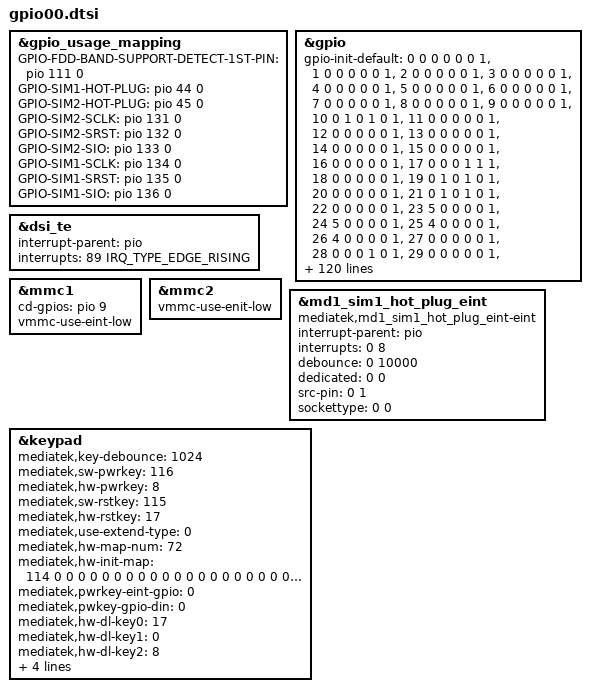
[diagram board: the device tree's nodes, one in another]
// SPDX-License-Identifier: (GPL-2.0 OR MIT)
/*
 * Copyright (C) 2025 MediaTek Inc.
 */
/*
 * Generated by MTK SP DrvGen Version: 3.5.160809 for MT6991.
 * 2025-01-08 15:47:34
 * Do Not Modify The File.
 * Copyright Mediatek Inc. (c) 2016.
 */

/*************************
 * ADC DTSI File
 ************************/



/*************************
 * CLK_BUF DTSI File
 ************************/



/*************************
 * I2C DTSI File
 ************************/



/*************************
 * GPIO DTSI File
 ************************/

&gpio_usage_mapping {
	GPIO-FDD-BAND-SUPPORT-DETECT-1ST-PIN = <&pio 111 0>;
	GPIO-SIM1-HOT-PLUG = <&pio 44 0>;
	GPIO-SIM2-HOT-PLUG = <&pio 45 0>;
	GPIO-SIM2-SCLK = <&pio 131 0>;
	GPIO-SIM2-SRST = <&pio 132 0>;
	GPIO-SIM2-SIO = <&pio 133 0>;
	GPIO-SIM1-SCLK = <&pio 134 0>;
	GPIO-SIM1-SRST = <&pio 135 0>;
	GPIO-SIM1-SIO = <&pio 136 0>;
};

#if 0
&mt6373_gpio{
	/* gpio1 and gpio2 has been reserved */
	mt6373-gpio-init-default = <3 0 0 0 1 0 0>,
	<4 0 0 0 1 0 0>,
	<5 0 0 0 1 0 0>,
	<6 0 0 0 1 0 0>,
	<7 0 0 0 1 0 0>,
	<8 0 0 0 1 0 0>,
	<9 0 0 0 1 0 0>,
	<10 0 0 0 1 0 0>,
	<11 0 0 0 1 1 0>,
	<12 0 0 0 1 1 0>,
	<13 0 0 0 0 0 0>;
};
#endif

&gpio{
	gpio-init-default = <0 0 0 0 0 0 1>,
		<1 0 0 0 0 0 1>,
		<2 0 0 0 0 0 1>,
		<3 0 0 0 0 0 1>,
		<4 0 0 0 0 0 1>,
		<5 0 0 0 0 0 1>,
		<6 0 0 0 0 0 1>,
		<7 0 0 0 0 0 1>,
		<8 0 0 0 0 0 1>,
		<9 0 0 0 0 0 1>,
		<10 0 1 0 1 0 1>,
		<11 0 0 0 0 0 1>,
		<12 0 0 0 0 0 1>,
		<13 0 0 0 0 0 1>,
		<14 0 0 0 0 0 1>,
		<15 0 0 0 0 0 1>,
		<16 0 0 0 0 0 1>,
		<17 0 0 0 1 1 1>,
		<18 0 0 0 0 0 1>,
		<19 0 1 0 1 0 1>,
		<20 0 0 0 0 0 1>,
		<21 0 1 0 1 0 1>,
		<22 0 0 0 0 0 1>,
		<23 5 0 0 0 0 1>,
		<24 5 0 0 0 0 1>,
		<25 4 0 0 0 0 1>,
		<26 4 0 0 0 0 1>,
		<27 0 0 0 0 0 1>,
		<28 0 0 0 1 0 1>,
		<29 0 0 0 0 0 1>,
		<30 0 0 0 0 0 1>,
		<31 0 0 0 0 0 1>,
		<32 0 0 0 0 0 1>,
		<33 0 0 0 0 0 1>,
		<34 0 1 0 1 0 1>,
		<35 0 0 0 0 0 1>,
		<36 0 1 0 1 0 1>,
		<37 0 0 0 1 0 1>,
		<38 0 0 0 1 0 1>,
		<39 0 1 0 1 0 1>,
		<40 4 0 0 1 0 1>,
		<41 4 0 0 1 0 1>,
		<42 4 0 0 1 0 1>,
		<43 4 0 0 1 0 1>,
		<44 1 0 0 0 0 1>,
		<45 0 0 0 1 0 1>,
		<46 1 0 0 1 1 1>,
		<47 1 0 0 1 1 1>,
		<48 1 0 0 1 1 1>,
		<49 1 0 0 1 1 1>,
		<50 1 0 0 1 1 1>,
		<51 1 0 0 1 1 1>,
		<52 0 0 0 1 0 1>,
		<53 0 0 0 1 0 1>,
		<54 0 0 0 1 0 1>,
		<55 0 0 0 1 0 1>,
		<56 1 0 0 0 0 1>,
		<57 1 0 0 0 0 1>,
		<58 0 0 0 1 0 1>,
		<59 0 0 0 1 0 1>,
		<60 1 0 0 1 1 1>,
		<61 1 0 0 0 0 1>,
		<62 1 0 0 0 0 1>,
		<63 1 0 0 0 0 1>,
		<64 1 0 0 1 1 1>,
		<65 0 0 0 1 0 1>,
		<66 1 0 0 0 0 1>,
		<67 1 0 0 0 0 1>,
		<68 1 0 0 0 0 1>,
		<69 1 0 0 1 0 1>,
		<70 0 0 0 1 0 1>,
		<71 0 0 0 0 0 1>,
		<72 0 0 0 1 0 1>,
		<73 0 0 0 1 0 1>,
		<74 0 0 0 1 0 1>,
		<75 1 0 0 0 0 1>,
		<76 1 0 0 0 0 1>,
		<77 1 0 0 1 0 1>,
		<78 1 0 0 1 0 1>,
		<79 0 1 0 1 0 1>,
		<80 0 1 0 1 0 1>,
		<81 2 0 0 1 0 1>,
		<82 2 0 0 1 1 1>,
		<83 2 0 0 1 0 1>,
		<84 2 0 0 1 0 1>,
		<85 1 0 0 1 0 1>,
		<86 1 0 0 1 1 1>,
		<87 1 0 0 1 0 1>,
		<88 1 0 0 1 0 1>,
		<89 1 0 0 1 0 1>,
		<90 1 0 0 1 0 1>,
		<91 0 1 0 1 0 1>,
		<92 0 1 0 1 0 1>,
		<93 0 0 0 1 0 1>,
		<94 0 0 0 1 0 1>,
		<95 2 0 0 0 0 1>,
		<96 2 0 0 0 0 1>,
		<97 2 0 0 1 0 1>,
		<98 2 0 0 1 0 1>,
		<99 1 0 0 1 1 1>,
		<100 1 0 0 1 1 1>,
		<101 1 0 0 1 1 1>,
		<102 1 0 0 1 1 1>,
		<103 0 0 0 1 0 1>,
		<104 1 0 0 1 1 1>,
		<105 1 0 0 1 1 1>,
		<106 0 0 0 0 0 1>,
		<107 0 0 0 0 0 1>,
		<108 0 0 0 0 0 1>,
		<109 0 0 0 0 0 1>,
		<110 0 1 0 1 0 1>,
		<111 0 0 0 0 0 1>,
		<112 0 0 0 0 0 1>,
		<113 0 0 0 0 0 1>,
		<114 0 1 0 1 0 1>,
		<115 0 0 0 0 0 1>,
		<116 0 0 0 0 0 1>,
		<117 0 0 0 0 0 1>,
		<118 0 0 0 0 0 1>,
		<119 0 0 0 0 0 1>,
		<120 0 1 0 1 0 1>,
		<121 0 1 0 1 0 1>,
		<123 1 0 0 1 1 1>,
		<124 1 0 0 1 1 1>,
		<125 1 0 0 0 0 1>,
		<126 1 0 0 1 1 1>,
		<127 1 0 0 1 1 1>,
		<128 1 0 0 1 1 1>,
		<129 1 0 0 1 1 1>,
		<130 1 0 0 1 1 1>,
		<131 1 0 0 0 0 1>,
		<132 1 0 0 0 0 1>,
		<133 1 0 0 1 1 1>,
		<134 1 0 0 0 0 1>,
		<135 1 0 0 0 0 1>,
		<136 1 0 0 1 1 1>,
		<137 0 0 0 0 0 0>,
		<138 0 0 0 0 0 0>,
		<139 0 0 0 0 0 0>,
		<140 0 0 0 0 0 0>,
		<141 1 0 0 0 0 0>,
		<142 1 0 0 1 0 0>,
		<143 1 0 0 0 0 0>,
		<144 1 0 0 1 0 0>,
		<145 0 0 0 1 0 1>,
		<146 0 0 0 1 0 1>,
		<147 0 0 0 0 0 1>,
		<148 0 0 0 0 0 1>,
		<149 0 0 0 0 0 1>,
		<150 0 0 0 0 0 1>,
		<151 0 0 0 1 0 1>,
		<152 0 0 0 0 0 1>,
		<153 1 0 0 1 0 1>,
		<154 1 0 0 1 0 1>,
		<155 1 0 0 1 0 1>,
		<156 1 0 0 1 0 1>,
		<157 0 0 0 0 0 1>,
		<158 0 0 0 0 0 1>,
		<159 0 0 0 0 0 1>,
		<160 1 0 0 0 0 1>,
		<161 1 0 0 1 1 1>,
		<162 1 0 0 0 0 1>,
		<163 1 0 0 1 1 1>,
		<164 1 0 0 1 1 1>,
		<165 1 0 0 1 1 1>,
		<166 0 0 0 1 0 1>,
		<167 0 0 0 1 0 1>,
		<168 2 0 0 1 0 1>,
		<169 2 0 0 1 0 1>,
		<170 2 0 0 1 0 1>,
		<171 2 0 0 1 0 1>,
		<172 0 0 0 0 0 1>,
		<173 0 0 0 0 0 1>,
		<174 0 1 0 1 0 1>,
		<175 0 1 0 1 0 1>,
		<176 1 0 0 1 1 1>,
		<177 1 0 0 1 1 1>,
		<178 1 0 0 1 0 1>,
		<179 1 0 0 1 0 1>,
		<180 0 1 0 1 0 1>,
		<181 0 0 0 0 0 1>,
		<182 1 0 0 0 0 1>,
		<183 1 0 0 0 0 1>,
		<184 1 0 0 0 0 1>,
		<185 1 0 0 0 0 1>,
		<186 0 1 0 1 0 1>,
		<187 0 1 0 1 0 1>,
		<188 1 0 0 1 1 1>,
		<189 1 0 0 1 1 1>,
		<190 1 0 0 1 1 1>,
		<191 1 0 0 1 1 1>,
		<192 1 0 0 1 0 1>,
		<193 0 0 0 1 0 1>,
		<194 1 0 0 1 1 1>,
		<195 1 0 0 1 1 1>,
		<196 1 0 0 1 0 1>,
		<197 0 0 0 1 0 1>,
		<198 1 0 0 1 1 1>,
		<199 1 0 0 1 1 1>,
		<200 1 0 0 1 1 1>,
		<201 1 0 0 1 1 1>,
		<202 1 0 0 1 1 1>,
		<203 1 0 0 1 1 1>,
		<204 1 0 0 0 0 1>,
		<205 1 0 0 0 0 1>,
		<206 0 1 0 1 0 1>,
		<207 0 1 0 1 0 1>,
		<208 0 1 0 1 0 1>,
		<209 0 1 0 1 0 1>,
		<210 1 0 0 1 0 1>,
		<211 0 1 0 1 0 1>,
		<212 0 0 0 1 0 1>,
		<213 0 1 0 1 0 1>,
		<214 2 0 0 0 0 1>,
		<215 2 0 0 0 0 1>,
		<216 0 0 0 0 0 1>,
		<217 1 0 0 1 0 1>,
		<218 0 1 0 1 0 1>,
		<219 7 0 0 1 0 1>,
		<220 7 0 0 1 0 1>,
		<221 7 0 0 1 0 1>,
		<222 7 0 0 0 0 1>,
		<223 7 0 0 1 0 1>,
		<224 0 0 0 0 0 1>,
		<225 0 1 0 1 0 1>,
		<226 0 1 0 1 0 1>,
		<227 0 0 0 0 0 1>,
		<228 0 1 0 1 0 1>,
		<229 0 0 0 1 0 1>,
		<230 0 0 0 1 0 1>,
		<231 0 0 0 1 0 1>,
		<232 0 0 0 1 0 1>,
		<233 0 0 0 1 0 1>,
		<234 0 0 0 1 0 1>,
		<235 0 0 0 1 0 1>,
		<236 0 0 0 1 0 1>,
		<237 0 0 0 1 0 1>,
		<238 0 0 0 1 0 1>,
		<239 0 0 0 1 0 1>,
		<240 0 0 0 1 0 1>,
		<241 0 0 0 1 0 1>,
		<242 0 0 0 1 0 1>,
		<243 0 0 0 1 0 1>,
		<244 0 0 0 1 0 1>,
		<245 0 0 0 1 0 1>,
		<246 0 0 0 1 0 1>,
		<247 0 0 0 1 0 1>,
		<248 0 0 0 1 0 1>,
		<249 0 0 0 1 0 1>,
		<250 0 0 0 1 0 1>,
		<251 0 0 0 1 0 1>,
		<252 0 0 0 1 0 1>,
		<253 0 0 0 1 0 1>,
		<254 0 0 0 1 0 0>,
		<255 0 0 0 1 0 0>,
		<256 0 0 0 1 0 0>,
		<257 0 0 0 1 0 0>,
		<258 0 0 0 1 0 0>,
		<259 0 0 0 1 0 0>,
		<260 0 0 0 1 0 0>,
		<261 0 0 0 1 0 0>,
		<262 0 0 0 1 0 0>,
		<263 0 0 0 1 0 0>,
		<264 0 0 0 1 0 0>,
		<265 0 0 0 1 0 0>,
		<266 0 0 0 1 0 0>,
		<267 0 0 0 1 0 0>,
		<268 0 0 0 1 0 0>,
		<269 0 0 0 1 0 0>,
		<270 0 0 0 1 0 0>;
};


/*************************
 * EINT DTSI File
 ************************/

#include <dt-bindings/interrupt-controller/irq.h>
#include <dt-bindings/interrupt-controller/arm-gic.h>
#include <dt-bindings/gpio/gpio.h>

&dsi_te {
	interrupt-parent = <&pio>;
	interrupts = <89 IRQ_TYPE_EDGE_RISING>;
	status = "okay";
};


&mmc1 {
	cd-gpios = <&pio 9 GPIO_ACTIVE_HIGH>;
	vmmc-use-eint-low;
};

&mmc2 {
	vmmc-use-enit-low;
};

/*************************
 * MD1_EINT DTSI File
 ************************/

&md1_sim1_hot_plug_eint {
	compatible = "mediatek,md1_sim1_hot_plug_eint-eint";
	interrupt-parent = <&pio>;
	interrupts = <0 8>;
	debounce = <0 10000>;
	dedicated = <0 0>;
	src-pin = <0 1>;
	sockettype = <0 0>;
	status = "okay";
};

/*************************
 * PMIC DTSI File
 ************************/



/*************************
 * POWER DTSI File
 ************************/



/*************************
 * KPD DTSI File
 ************************/

&keypad {
	mediatek,key-debounce = <1024>;
	mediatek,sw-pwrkey = <116>;
	mediatek,hw-pwrkey = <8>;
	mediatek,sw-rstkey  = <115>;
	mediatek,hw-rstkey = <17>;
	mediatek,use-extend-type = <0>;
	/*HW Keycode [0~71] -> Linux Keycode*/
	mediatek,hw-map-num = <72>;
	mediatek,hw-init-map = <114 0 0 0 0 0 0 0 0 0 0 0 0 0 0 0 0 0 0 0 0 0 0 0
				0 0 0 0 0 0 0 0 0 0 0 0 0 0 0 0 0 0 0 0 0 0 0 0
				0 0 0 0 0 0 0 0 0 0 0 0 0 0 0 0 0 0 0 0 0 0 0 0 >;
	mediatek,pwrkey-eint-gpio = <0>;
	mediatek,pwkey-gpio-din  = <0>;
	mediatek,hw-dl-key0 = <17>;
	mediatek,hw-dl-key1 = <0>;
	mediatek,hw-dl-key2 = <8>;
	mediatek,hw-recovery-key = <17>;
	mediatek,hw-factory-key = <0>;
	mediatek,gpio-key-index = <17>;
	/*factory-key-type*/
	/*0: Keypad IP key*/
	/*1: GPIO key*/
	/*2: HOME2 key*/
	mediatek,factory-key-type = <1>;
	status = "okay";
};


